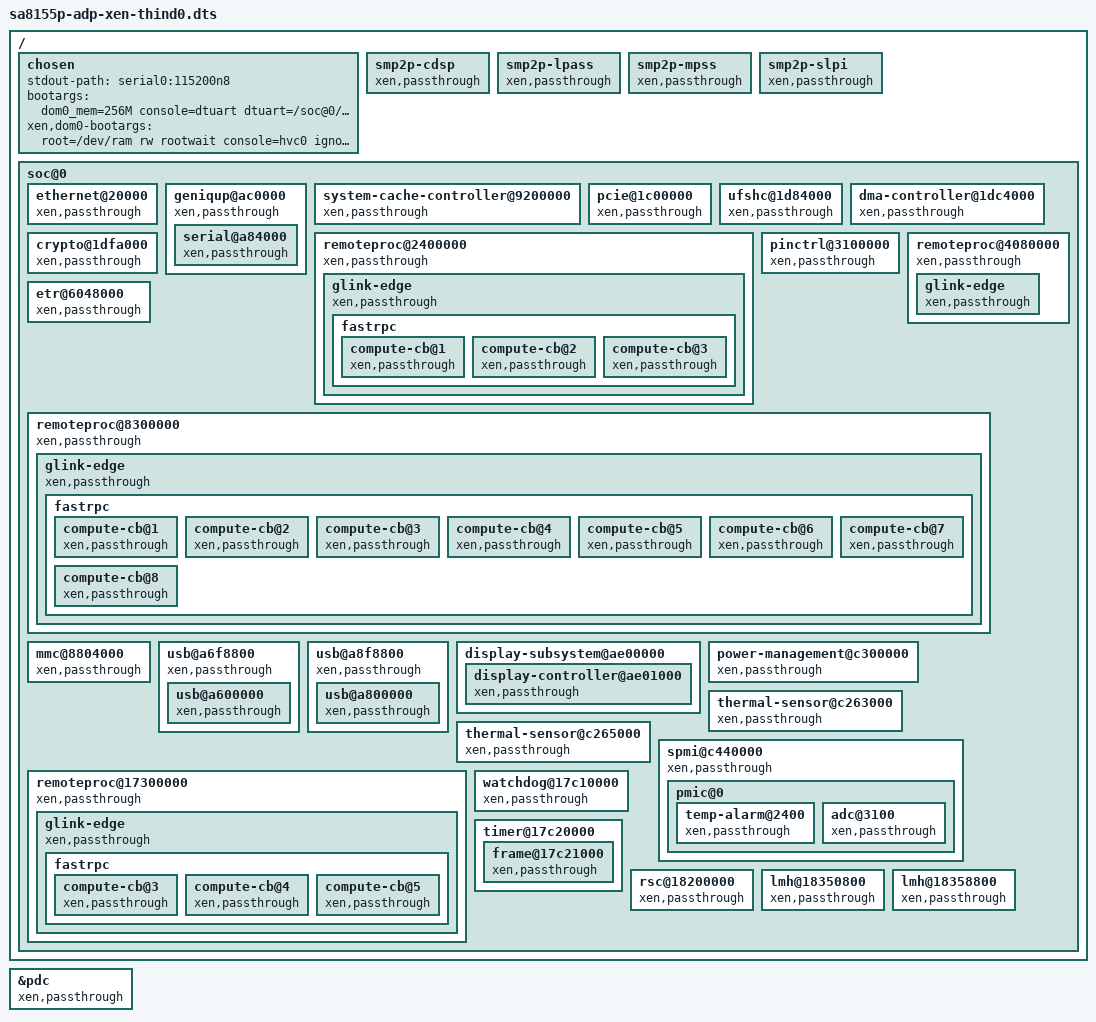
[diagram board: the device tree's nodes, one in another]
#include "sa8155p-adp-xen.dts"

// this is autogenerated dts part
/ {
	chosen {
		stdout-path = "serial0:115200n8";
		bootargs = "dom0_mem=256M console=dtuart dtuart=/soc@0/geniqup@ac0000/serial@a90000 dom0_max_vcpus=2 loglvl=all xsm=flask flask=permissive bootscrub=1";
		xen,dom0-bootargs = "root=/dev/ram rw rootwait console=hvc0 ignore_loglevel clk_ignore_unused boot_delay=100";
	};
	smp2p-cdsp {
		xen,passthrough;
	};
	smp2p-lpass {
		xen,passthrough;
	};
	smp2p-mpss {
		xen,passthrough;
	};
	smp2p-slpi {
		xen,passthrough;
	};
	soc@0 {
		ethernet@20000 {
			xen,passthrough;
		};
		geniqup@ac0000 {
			xen,passthrough;
			serial@a84000 {
				xen,passthrough;
			};
		};
		system-cache-controller@9200000 {
			xen,passthrough;
		};
		pcie@1c00000 {
			xen,passthrough;
		};
		ufshc@1d84000 {
			xen,passthrough;
		};
		dma-controller@1dc4000 {
			xen,passthrough;
		};
		crypto@1dfa000 {
			xen,passthrough;
		};
		remoteproc@2400000 {
			xen,passthrough;
			glink-edge {
				xen,passthrough;
				fastrpc {
					compute-cb@1 {
						xen,passthrough;
					};
					compute-cb@2 {
						xen,passthrough;
					};
					compute-cb@3 {
						xen,passthrough;
					};
				};
			};
		};
		pinctrl@3100000 {
			xen,passthrough;
		};
		remoteproc@4080000 {
			xen,passthrough;
			glink-edge {
				xen,passthrough;
			};
		};
		etr@6048000 {
			xen,passthrough;
		};
		remoteproc@8300000 {
			xen,passthrough;
			glink-edge {
				xen,passthrough;
				fastrpc {
					compute-cb@1 {
						xen,passthrough;
					};
					compute-cb@2 {
						xen,passthrough;
					};
					compute-cb@3 {
						xen,passthrough;
					};
					compute-cb@4 {
						xen,passthrough;
					};
					compute-cb@5 {
						xen,passthrough;
					};
					compute-cb@6 {
						xen,passthrough;
					};
					compute-cb@7 {
						xen,passthrough;
					};
					compute-cb@8 {
						xen,passthrough;
					};
				};
			};
		};
		mmc@8804000 {
			xen,passthrough;
		};
		usb@a6f8800 {
			xen,passthrough;
			usb@a600000 {
				xen,passthrough;
			};
		};
		usb@a8f8800 {
			xen,passthrough;
			usb@a800000 {
				xen,passthrough;
			};
		};
		display-subsystem@ae00000 {
			display-controller@ae01000 {
				xen,passthrough;
			};
		};
		power-management@c300000 {
			xen,passthrough;
		};
		thermal-sensor@c263000 {
			xen,passthrough;
		};
		thermal-sensor@c265000 {
			xen,passthrough;
		};
		spmi@c440000 {
			xen,passthrough;
			pmic@0 {
				temp-alarm@2400 {
					xen,passthrough;
				};
				adc@3100 {
					xen,passthrough;
				};
			};
		};
		remoteproc@17300000 {
			xen,passthrough;
			glink-edge {
				xen,passthrough;
				fastrpc {
					compute-cb@3 {
						xen,passthrough;
					};
					compute-cb@4 {
						xen,passthrough;
					};
					compute-cb@5 {
						xen,passthrough;
					};
				};
			};
		};
		watchdog@17c10000 {
			xen,passthrough;
		};
		timer@17c20000 {
			frame@17c21000 {
				xen,passthrough;
			};
		};
		rsc@18200000 {
			xen,passthrough;
		};
		lmh@18350800 {
			xen,passthrough;
		};
		lmh@18358800 {
			xen,passthrough;
		};
	};
};

&pdc { xen,passthrough; };

/* &hyp_mem     { xen,passthrough; }; */
/* &xbl_mem     { xen,passthrough; }; */
/* &aop_cmd_db  { xen,passthrough; }; */
/* &smem_mem    { xen,passthrough; }; */
/* &tz_mem      { xen,passthrough; }; */
/* &rmtfs_mem   { xen,passthrough; }; */
/* &camera_mem  { xen,passthrough; }; */
/* &wlan_mem    { xen,passthrough; }; */
/* &npu_mem     { xen,passthrough; }; */
/* &adsp_mem    { xen,passthrough; }; */
/* &mpss_mem    { xen,passthrough; }; */
/* &slpi_mem    { xen,passthrough; }; */
/* &ipa_fw_mem  { xen,passthrough; }; */
/* &ipa_gsi_mem { xen,passthrough; }; */
/* &gpu_mem     { xen,passthrough; }; */
/* &spss_mem    { xen,passthrough; }; */
/* &cdsp_mem    { xen,passthrough; }; */
/* &qseecom_mem { xen,passthrough; }; */
